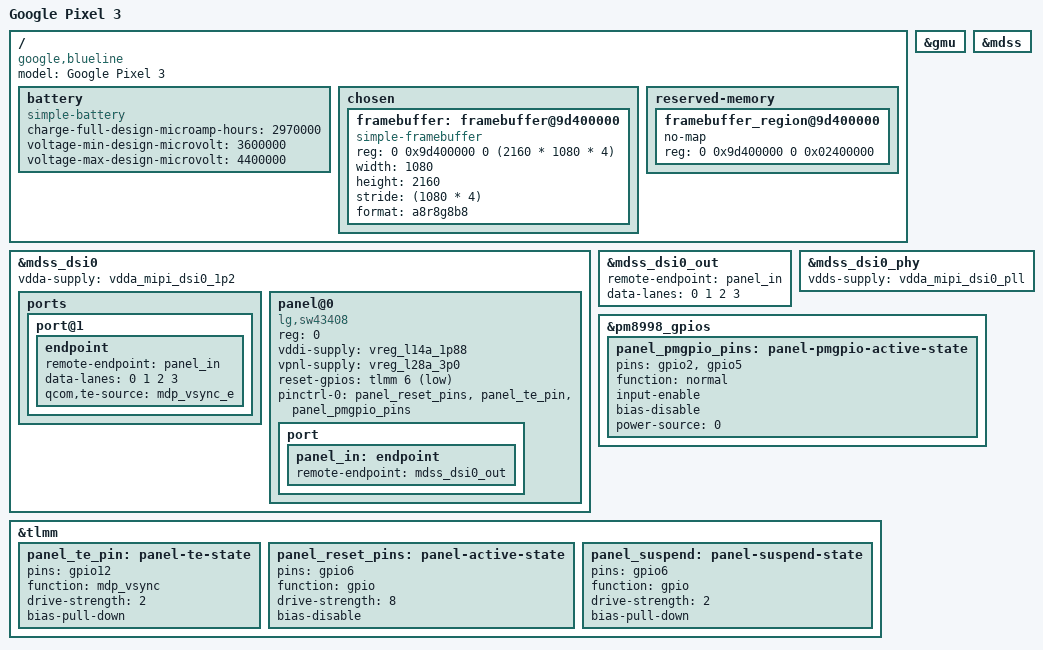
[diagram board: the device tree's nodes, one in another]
// SPDX-License-Identifier: GPL-2.0-only

/dts-v1/;

#include "sdm845-google-common.dtsi"

/ {
	model = "Google Pixel 3";
	compatible = "google,blueline", "qcom,sdm845";

	battery: battery {
		compatible = "simple-battery";

		charge-full-design-microamp-hours = <2970000>;
		voltage-min-design-microvolt = <3600000>;
		voltage-max-design-microvolt = <4400000>;
	};

	chosen {
		#address-cells = <2>;
		#size-cells = <2>;
		ranges;

		/* for u-boot */
		framebuffer: framebuffer@9d400000 {
			compatible = "simple-framebuffer";
			reg = <0 0x9d400000 0 (2160 * 1080 * 4)>;
			width = <1080>;
			height = <2160>;
			stride = <(1080 * 4)>;
			format = "a8r8g8b8";
		};
	};

	reserved-memory {
		framebuffer_region@9d400000 {
			no-map;
			reg = <0 0x9d400000 0 0x02400000>; // FIXME
		};
	};
};

&gmu {
	status = "okay";
};

&mdss {
	status = "okay";
};

&mdss_dsi0 {
	status = "okay";
	vdda-supply = <&vdda_mipi_dsi0_1p2>;

	ports {
		port@1 {
			endpoint {
				remote-endpoint = <&panel_in>;
				data-lanes = <0 1 2 3>;
				qcom,te-source = "mdp_vsync_e";
			};
		};
	};

	panel@0 {
		compatible = "lg,sw43408";
		reg = <0>;

		vddi-supply = <&vreg_l14a_1p88>;
		vpnl-supply = <&vreg_l28a_3p0>;

		reset-gpios = <&tlmm 6 GPIO_ACTIVE_LOW>;

		pinctrl-names = "default";
		pinctrl-0 = <&panel_reset_pins &panel_te_pin &panel_pmgpio_pins>;

		port {
			panel_in: endpoint {
				remote-endpoint = <&mdss_dsi0_out>;
			};
		};
	};
};

&mdss_dsi0_out {
	remote-endpoint = <&panel_in>;
	data-lanes = <0 1 2 3>;
};

&mdss_dsi0_phy {
	vdds-supply = <&vdda_mipi_dsi0_pll>;

	status = "okay";
};

&pm8998_gpios {
	panel_pmgpio_pins: panel-pmgpio-active-state {
		pins = "gpio2", "gpio5";
		function = "normal";
		input-enable;
		bias-disable;
		power-source = <0>;
	};
};

&tlmm {
	panel_te_pin: panel-te-state {
		pins = "gpio12";
		function = "mdp_vsync";
		drive-strength = <2>;
		bias-pull-down;
	};

	panel_reset_pins: panel-active-state {
		pins = "gpio6";
		function = "gpio";
		drive-strength = <8>;
		bias-disable;
	};

	panel_suspend: panel-suspend-state {
		pins = "gpio6";
		function = "gpio";
		drive-strength = <2>;
		bias-pull-down;
	};

};
